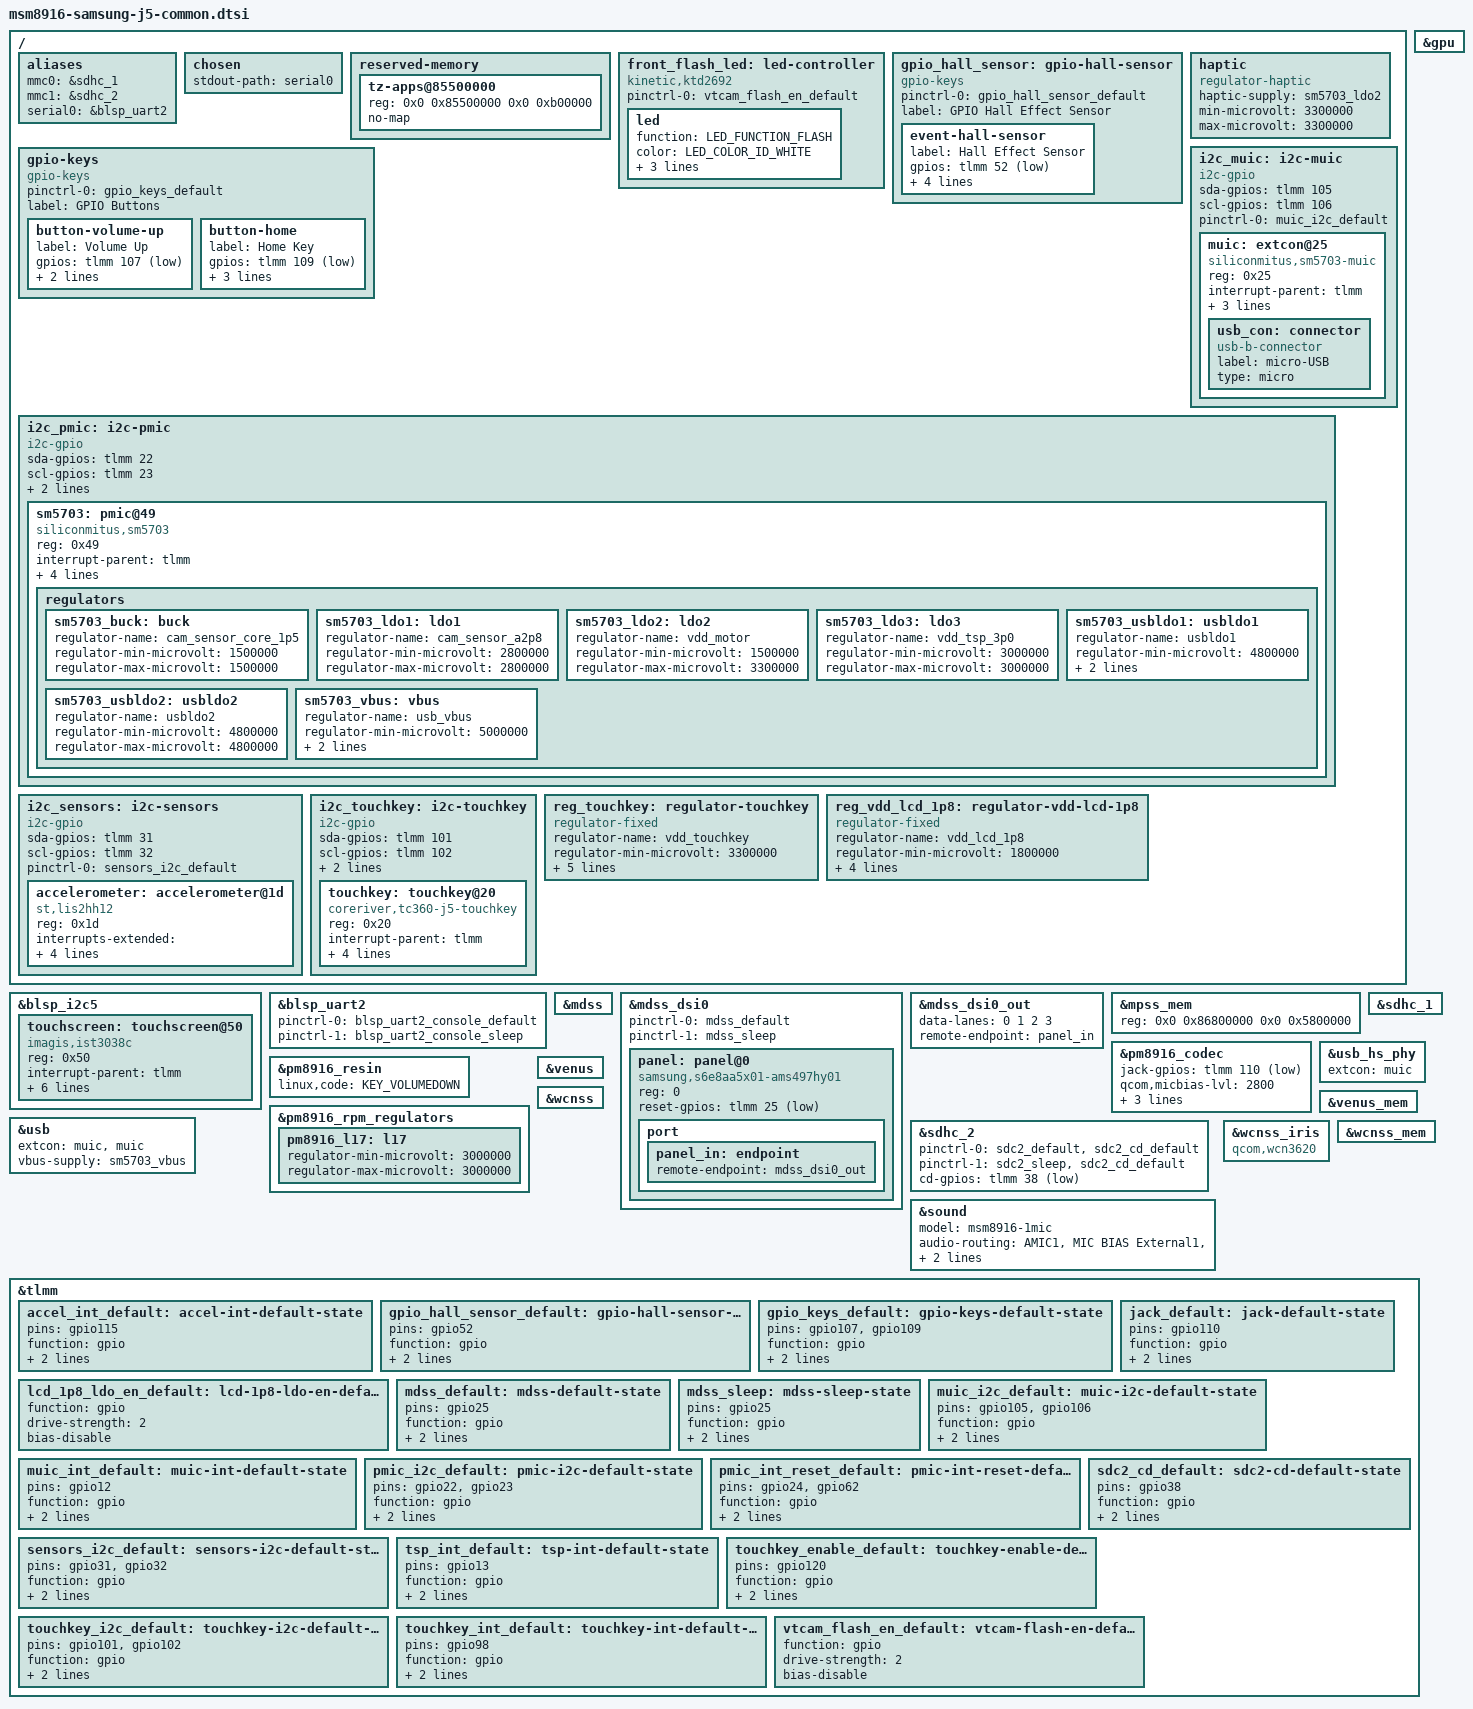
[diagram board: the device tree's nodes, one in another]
// SPDX-License-Identifier: GPL-2.0-only

#include "msm8916-pm8916.dtsi"
#include "msm8916-modem-qdsp6.dtsi"

#include <dt-bindings/gpio/gpio.h>
#include <dt-bindings/input/input.h>
#include <dt-bindings/interrupt-controller/irq.h>
#include <dt-bindings/leds/common.h>

/ {
	aliases {
		mmc0 = &sdhc_1; /* eMMC */
		mmc1 = &sdhc_2; /* SD card */
		serial0 = &blsp_uart2;
	};

	chosen {
		stdout-path = "serial0";
	};

	reserved-memory {
		/* Additional memory used by Samsung firmware modifications */
		tz-apps@85500000 {
			reg = <0x0 0x85500000 0x0 0xb00000>;
			no-map;
		};
	};

	front_flash_led: led-controller {
		compatible = "kinetic,ktd2692";
		pinctrl-0 = <&vtcam_flash_en_default>;
		pinctrl-names = "default";

		led {
			function = LED_FUNCTION_FLASH;
			color = <LED_COLOR_ID_WHITE>;

			led-max-microamp = <300000>;
			flash-max-microamp = <1500000>;
			flash-max-timeout-us = <1835000>;
		};
	};

	gpio_hall_sensor: gpio-hall-sensor {
		compatible = "gpio-keys";

		pinctrl-names = "default";
		pinctrl-0 = <&gpio_hall_sensor_default>;

		label = "GPIO Hall Effect Sensor";

		event-hall-sensor {
			label = "Hall Effect Sensor";
			gpios = <&tlmm 52 GPIO_ACTIVE_LOW>;
			linux,input-type = <EV_SW>;
			linux,code = <SW_LID>;
			linux,can-disable;
			wakeup-source;
		};
	};

	gpio-keys {
		compatible = "gpio-keys";

		pinctrl-names = "default";
		pinctrl-0 = <&gpio_keys_default>;

		label = "GPIO Buttons";

		button-volume-up {
			label = "Volume Up";
			gpios = <&tlmm 107 GPIO_ACTIVE_LOW>;
			linux,code = <KEY_VOLUMEUP>;
			debounce-interval = <15>;
		};

		button-home {
			label = "Home Key";
			gpios = <&tlmm 109 GPIO_ACTIVE_LOW>;
			linux,code = <KEY_HOMEPAGE>;
			debounce-interval = <15>;
			wakeup-source;
		};
	};

	haptic {
		compatible = "regulator-haptic";
		haptic-supply = <&sm5703_ldo2>;
		min-microvolt = <3300000>;
		max-microvolt = <3300000>;
	};

	i2c_muic: i2c-muic {
		compatible = "i2c-gpio";
		sda-gpios = <&tlmm 105 (GPIO_ACTIVE_HIGH|GPIO_OPEN_DRAIN)>;
		scl-gpios = <&tlmm 106 (GPIO_ACTIVE_HIGH|GPIO_OPEN_DRAIN)>;

		pinctrl-names = "default";
		pinctrl-0 = <&muic_i2c_default>;

		#address-cells = <1>;
		#size-cells = <0>;

		muic: extcon@25 {
			compatible = "siliconmitus,sm5703-muic";
			reg = <0x25>;

			interrupt-parent = <&tlmm>;
			interrupts = <12 IRQ_TYPE_EDGE_FALLING>;
			wakeup-source;

			pinctrl-names = "default";
			pinctrl-0 = <&muic_int_default>;

			usb_con: connector {
				compatible = "usb-b-connector";
				label = "micro-USB";
				type = "micro";
			};
		};
	};

	i2c_pmic: i2c-pmic {
		compatible = "i2c-gpio";
		sda-gpios = <&tlmm 22 (GPIO_ACTIVE_HIGH | GPIO_OPEN_DRAIN)>;
		scl-gpios = <&tlmm 23 (GPIO_ACTIVE_HIGH | GPIO_OPEN_DRAIN)>;
		i2c-gpio,delay-us = <2>;

		pinctrl-0 = <&pmic_i2c_default>;
		pinctrl-names = "default";

		#address-cells = <1>;
		#size-cells = <0>;

		sm5703: pmic@49 {
			compatible = "siliconmitus,sm5703";
			reg = <0x49>;

			interrupt-parent = <&tlmm>;
			interrupts = <62 IRQ_TYPE_EDGE_FALLING>;
			reset-gpios = <&tlmm 24 GPIO_ACTIVE_LOW>;

			pinctrl-0 = <&pmic_int_reset_default>;
			pinctrl-names = "default";
			wakeup-source;

			regulators {
				sm5703_buck: buck {
					regulator-name = "cam_sensor_core_1p5";
					regulator-min-microvolt = <1500000>;
					regulator-max-microvolt = <1500000>;
				};

				sm5703_ldo1: ldo1 {
					regulator-name = "cam_sensor_a2p8";
					regulator-min-microvolt = <2800000>;
					regulator-max-microvolt = <2800000>;
				};

				sm5703_ldo2: ldo2 {
					regulator-name = "vdd_motor";
					regulator-min-microvolt = <1500000>;
					regulator-max-microvolt = <3300000>;
				};

				sm5703_ldo3: ldo3 {
					regulator-name = "vdd_tsp_3p0";
					regulator-min-microvolt = <3000000>;
					regulator-max-microvolt = <3000000>;
				};

				sm5703_usbldo1: usbldo1 {
					regulator-name = "usbldo1";
					regulator-min-microvolt = <4800000>;
					regulator-max-microvolt = <4800000>;
					regulator-always-on;
				};

				sm5703_usbldo2: usbldo2 {
					regulator-name = "usbldo2";
					regulator-min-microvolt = <4800000>;
					regulator-max-microvolt = <4800000>;
				};

				sm5703_vbus: vbus {
					regulator-name = "usb_vbus";
					regulator-min-microvolt = <5000000>;
					regulator-max-microvolt = <5000000>;
					regulator-max-microamp = <1200000>;
				};
			};
		};
	};

	i2c_sensors: i2c-sensors {
		compatible = "i2c-gpio";

		sda-gpios = <&tlmm 31 (GPIO_ACTIVE_HIGH|GPIO_OPEN_DRAIN)>;
		scl-gpios = <&tlmm 32 (GPIO_ACTIVE_HIGH|GPIO_OPEN_DRAIN)>;

		pinctrl-0 = <&sensors_i2c_default>;
		pinctrl-names = "default";

		#address-cells = <1>;
		#size-cells = <0>;

		accelerometer: accelerometer@1d {
			compatible = "st,lis2hh12";
			reg = <0x1d>;

			interrupts-extended = <&tlmm 115 IRQ_TYPE_LEVEL_HIGH>;

			pinctrl-0 = <&accel_int_default>;
			pinctrl-names = "default";

			st,drdy-int-pin = <1>;

			/* Match the axis mapping used by the Samsung K2HH driver. */
			mount-matrix = "-1", "0", "0",
				       "0", "-1", "0",
				       "0", "0", "-1";
		};
	};

	i2c_touchkey: i2c-touchkey {
		compatible = "i2c-gpio";
		sda-gpios = <&tlmm 101 (GPIO_ACTIVE_HIGH | GPIO_OPEN_DRAIN)>;
		scl-gpios = <&tlmm 102 (GPIO_ACTIVE_HIGH | GPIO_OPEN_DRAIN)>;
		i2c-gpio,delay-us = <1>;

		pinctrl-0 = <&touchkey_i2c_default>;
		pinctrl-names = "default";

		#address-cells = <1>;
		#size-cells = <0>;

		touchkey: touchkey@20 {
			compatible = "coreriver,tc360-j5-touchkey";
			reg = <0x20>;

			interrupt-parent = <&tlmm>;
			interrupts = <98 IRQ_TYPE_EDGE_FALLING>;

			vcc-supply = <&reg_touchkey>;
			linux,keycodes = <KEY_APPSELECT KEY_BACK>;

			pinctrl-0 = <&touchkey_int_default>;
			pinctrl-names = "default";
		};
	};

	reg_touchkey: regulator-touchkey {
		compatible = "regulator-fixed";
		regulator-name = "vdd_touchkey";
		regulator-min-microvolt = <3300000>;
		regulator-max-microvolt = <3300000>;

		gpio = <&tlmm 120 GPIO_ACTIVE_HIGH>;
		enable-active-high;
		startup-delay-us = <150000>;

		pinctrl-0 = <&touchkey_enable_default>;
		pinctrl-names = "default";
	};

	reg_vdd_lcd_1p8: regulator-vdd-lcd-1p8 {
		compatible = "regulator-fixed";
		regulator-name = "vdd_lcd_1p8";
		regulator-min-microvolt = <1800000>;
		regulator-max-microvolt = <1800000>;
		vin-supply = <&pm8916_s4>;

		enable-active-high;

		pinctrl-0 = <&lcd_1p8_ldo_en_default>;
		pinctrl-names = "default";
	};
};

&blsp_i2c5 {
	status = "okay";

	touchscreen: touchscreen@50 {
		compatible = "imagis,ist3038c";
		reg = <0x50>;

		interrupt-parent = <&tlmm>;
		interrupts = <13 IRQ_TYPE_EDGE_FALLING>;

		touchscreen-size-x = <720>;
		touchscreen-size-y = <1280>;

		vddio-supply = <&pm8916_l6>;
		extcon = <&muic>;

		pinctrl-0 = <&tsp_int_default>;
		pinctrl-names = "default";
	};
};

&blsp_uart2 {
	status = "okay";
	pinctrl-0 = <&blsp_uart2_console_default>;
	pinctrl-1 = <&blsp_uart2_console_sleep>;
	pinctrl-names = "default", "sleep";
};

&gpu {
	status = "okay";
};

&mdss {
	status = "okay";
};

&mdss_dsi0 {
	pinctrl-0 = <&mdss_default>;
	pinctrl-1 = <&mdss_sleep>;
	pinctrl-names = "default", "sleep";

	panel: panel@0 {
		reg = <0>;

		compatible = "samsung,s6e8aa5x01-ams497hy01";

		reset-gpios = <&tlmm 25 GPIO_ACTIVE_LOW>;

		port {
			panel_in: endpoint {
				remote-endpoint = <&mdss_dsi0_out>;
			};
		};
	};
};

&mdss_dsi0_out {
	data-lanes = <0 1 2 3>;
	remote-endpoint = <&panel_in>;
};

&mpss_mem {
	reg = <0x0 0x86800000 0x0 0x5800000>;
};

&pm8916_codec {
	jack-gpios = <&tlmm 110 GPIO_ACTIVE_LOW>;
	qcom,micbias-lvl = <2800>;
	qcom,mbhc-vthreshold-low = <75 150 237 450 500>;
	qcom,mbhc-vthreshold-high = <75 150 237 450 500>;

	pinctrl-0 = <&jack_default>;
	pinctrl-names = "default";
};

&pm8916_resin {
	status = "okay";
	linux,code = <KEY_VOLUMEDOWN>;
};

&pm8916_rpm_regulators {
	pm8916_l17: l17 {
		regulator-min-microvolt = <3000000>;
		regulator-max-microvolt = <3000000>;
	};
};

&sdhc_1 {
	status = "okay";
};

&sdhc_2 {
	status = "okay";

	pinctrl-names = "default", "sleep";
	pinctrl-0 = <&sdc2_default &sdc2_cd_default>;
	pinctrl-1 = <&sdc2_sleep &sdc2_cd_default>;

	cd-gpios = <&tlmm 38 GPIO_ACTIVE_LOW>;
};

&sound {
	model = "msm8916-1mic";
	audio-routing =
		"AMIC1", "MIC BIAS External1",
		"AMIC2", "MIC BIAS Internal2",
		"AMIC3", "MIC BIAS External1";
};

&usb {
	extcon = <&muic>, <&muic>;
	vbus-supply = <&sm5703_vbus>;
	status = "okay";
};

&usb_hs_phy {
	extcon = <&muic>;
};

&venus {
	status = "okay";
};

&venus_mem {
	status = "okay";
};

&wcnss {
	status = "okay";
};

&wcnss_iris {
	compatible = "qcom,wcn3620";
};

&wcnss_mem {
	status = "okay";
};

&tlmm {
	accel_int_default: accel-int-default-state {
		pins = "gpio115";
		function = "gpio";
		drive-strength = <2>;
		bias-disable;
	};

	gpio_hall_sensor_default: gpio-hall-sensor-default-state {
		pins = "gpio52";
		function = "gpio";

		drive-strength = <2>;
		bias-disable;
	};

	gpio_keys_default: gpio-keys-default-state {
		pins = "gpio107", "gpio109";
		function = "gpio";

		drive-strength = <2>;
		bias-pull-up;
	};

	jack_default: jack-default-state {
		pins = "gpio110";
		function = "gpio";
		drive-strength = <2>;
		bias-disable;
	};

	lcd_1p8_ldo_en_default: lcd-1p8-ldo-en-default-state {
		function = "gpio";

		drive-strength = <2>;
		bias-disable;
	};

	mdss_default: mdss-default-state {
		pins = "gpio25";
		function = "gpio";

		drive-strength = <8>;
		bias-disable;
	};

	mdss_sleep: mdss-sleep-state {
		pins = "gpio25";
		function = "gpio";

		drive-strength = <2>;
		bias-pull-down;
	};

	muic_i2c_default: muic-i2c-default-state {
		pins = "gpio105", "gpio106";
		function = "gpio";

		drive-strength = <2>;
		bias-disable;
	};

	muic_int_default: muic-int-default-state {
		pins = "gpio12";
		function = "gpio";

		drive-strength = <2>;
		bias-disable;
	};

	pmic_i2c_default: pmic-i2c-default-state {
		pins = "gpio22", "gpio23";
		function = "gpio";

		drive-strength = <2>;
		bias-disable;
	};

	pmic_int_reset_default: pmic-int-reset-default-state {
		pins = "gpio24", "gpio62";
		function = "gpio";

		drive-strength = <2>;
		bias-disable;
	};

	sdc2_cd_default: sdc2-cd-default-state {
		pins = "gpio38";
		function = "gpio";

		drive-strength = <2>;
		bias-disable;
	};

	sensors_i2c_default: sensors-i2c-default-state {
		pins = "gpio31", "gpio32";
		function = "gpio";
		drive-strength = <2>;
		bias-disable;
	};

	tsp_int_default: tsp-int-default-state {
		pins = "gpio13";
		function = "gpio";

		drive-strength = <2>;
		bias-disable;
	};

	touchkey_enable_default: touchkey-enable-default-state {
		pins = "gpio120";
		function = "gpio";

		drive-strength = <2>;
		bias-disable;
	};

	touchkey_i2c_default: touchkey-i2c-default-state {
		pins = "gpio101", "gpio102";
		function = "gpio";

		drive-strength = <2>;
		bias-disable;
	};

	touchkey_int_default: touchkey-int-default-state {
		pins = "gpio98";
		function = "gpio";

		drive-strength = <2>;
		bias-disable;
	};

	vtcam_flash_en_default: vtcam-flash-en-default-state {
		function = "gpio";
		drive-strength = <2>;
		bias-disable;
	};
};
